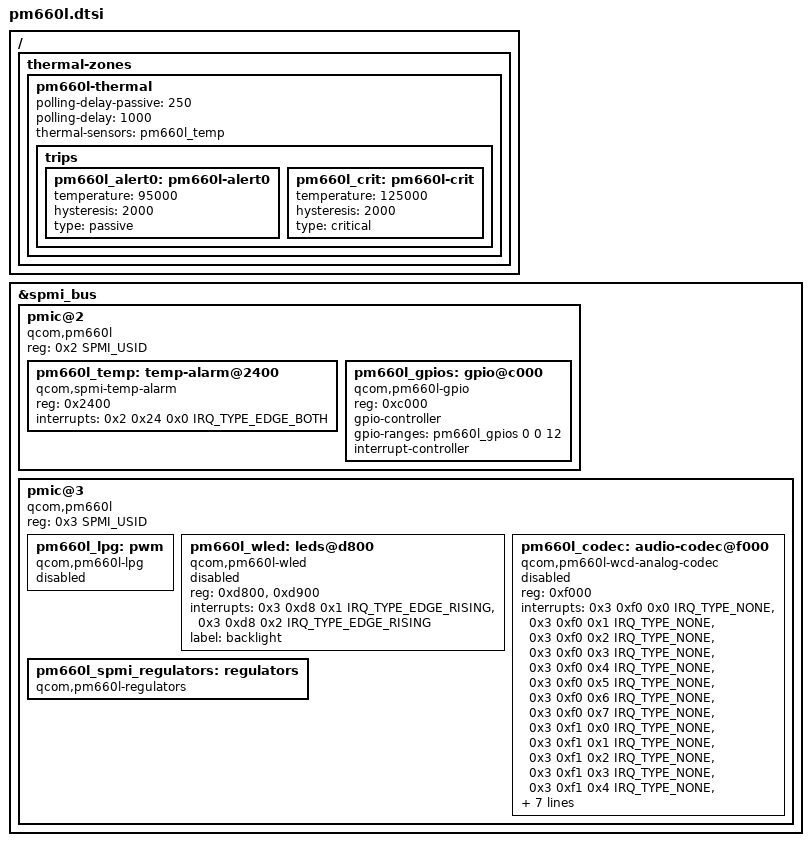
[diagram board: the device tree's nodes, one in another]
// SPDX-License-Identifier: BSD-3-Clause
/*
 * Copyright (c) 2020, Konrad Dybcio
 */

#include <dt-bindings/iio/qcom,spmi-vadc.h>
#include <dt-bindings/input/linux-event-codes.h>
#include <dt-bindings/interrupt-controller/irq.h>
#include <dt-bindings/spmi/spmi.h>
#include <dt-bindings/thermal/thermal.h>

/ {
	thermal-zones {
		pm660l-thermal {
			polling-delay-passive = <250>;
			polling-delay = <1000>;

			thermal-sensors = <&pm660l_temp>;

			trips {
				pm660l_alert0: pm660l-alert0 {
					temperature = <95000>;
					hysteresis = <2000>;
					type = "passive";
				};
				pm660l_crit: pm660l-crit {
					temperature = <125000>;
					hysteresis = <2000>;
					type = "critical";
				};
			};
		};
	};
};

&spmi_bus {

	pmic@2 {
		compatible = "qcom,pm660l", "qcom,spmi-pmic";
		reg = <0x2 SPMI_USID>;
		#address-cells = <1>;
		#size-cells = <0>;

		pm660l_temp: temp-alarm@2400 {
			compatible = "qcom,spmi-temp-alarm";
			reg = <0x2400>;
			interrupts = <0x2 0x24 0x0 IRQ_TYPE_EDGE_BOTH>;
			#thermal-sensor-cells = <0>;
		};

		pm660l_gpios: gpio@c000 {
			compatible = "qcom,pm660l-gpio", "qcom,spmi-gpio";
			reg = <0xc000>;
			gpio-controller;
			gpio-ranges = <&pm660l_gpios 0 0 12>;
			#gpio-cells = <2>;
			interrupt-controller;
			#interrupt-cells = <2>;
		};
	};

	pmic@3 {
		compatible = "qcom,pm660l", "qcom,spmi-pmic";
		reg = <0x3 SPMI_USID>;
		#address-cells = <1>;
		#size-cells = <0>;

		pm660l_lpg: pwm {
			compatible = "qcom,pm660l-lpg";

			status = "disabled";
		};

		pm660l_wled: leds@d800 {
			compatible = "qcom,pm660l-wled";
			reg = <0xd800>, <0xd900>;
			interrupts = <0x3 0xd8 0x1 IRQ_TYPE_EDGE_RISING>,
				     <0x3 0xd8 0x2 IRQ_TYPE_EDGE_RISING>;
			interrupt-names = "ovp", "short";
			label = "backlight";

			status = "disabled";
		};

		pm660l_codec: audio-codec@f000 {
			compatible = "qcom,pm660l-wcd-analog-codec",
				     "qcom,pm8916-wcd-analog-codec";
			reg = <0xf000>;
			interrupts = <0x3 0xf0 0x0 IRQ_TYPE_NONE>,
				     <0x3 0xf0 0x1 IRQ_TYPE_NONE>,
				     <0x3 0xf0 0x2 IRQ_TYPE_NONE>,
				     <0x3 0xf0 0x3 IRQ_TYPE_NONE>,
				     <0x3 0xf0 0x4 IRQ_TYPE_NONE>,
				     <0x3 0xf0 0x5 IRQ_TYPE_NONE>,
				     <0x3 0xf0 0x6 IRQ_TYPE_NONE>,
				     <0x3 0xf0 0x7 IRQ_TYPE_NONE>,
				     <0x3 0xf1 0x0 IRQ_TYPE_NONE>,
				     <0x3 0xf1 0x1 IRQ_TYPE_NONE>,
				     <0x3 0xf1 0x2 IRQ_TYPE_NONE>,
				     <0x3 0xf1 0x3 IRQ_TYPE_NONE>,
				     <0x3 0xf1 0x4 IRQ_TYPE_NONE>,
				     <0x3 0xf1 0x5 IRQ_TYPE_NONE>;
			interrupt-names = "cdc_spk_cnp_int",
					  "cdc_spk_clip_int",
					  "cdc_spk_ocp_int",
					  "mbhc_ins_rem_det1",
					  "mbhc_but_rel_det",
					  "mbhc_but_press_det",
					  "mbhc_ins_rem_det",
					  "mbhc_switch_int",
					  "cdc_ear_ocp_int",
					  "cdc_hphr_ocp_int",
					  "cdc_hphl_ocp_det",
					  "cdc_ear_cnp_int",
					  "cdc_hphr_cnp_int",
					  "cdc_hphl_cnp_int";
			qcom,hphl-jack-type-normally-open;
			qcom,gnd-jack-type-normally-open;
			qcom,mbhc-vthreshold-low = <75 150 237 437 437>;
			qcom,mbhc-vthreshold-high = <75 150 237 437 437>;
			qcom,micbias2-ext-cap;
			sound-name-prefix = "Analog";
			#sound-dai-cells = <1>;
			status = "disabled";
		};

		pm660l_spmi_regulators: regulators {
			compatible = "qcom,pm660l-regulators";
		};
	};
};

